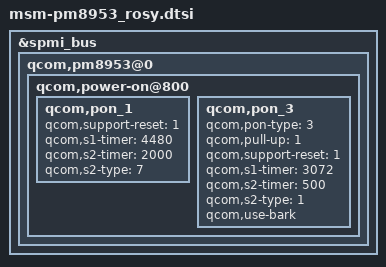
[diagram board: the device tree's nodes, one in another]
&spmi_bus {
	qcom,pm8953@0 {
		qcom,power-on@800 {
			qcom,pon_1 {
				qcom,support-reset = <1>;
				qcom,s1-timer = <4480>;
				qcom,s2-timer = <2000>;
				qcom,s2-type = <7>;
			};

			qcom,pon_3 {
				qcom,pon-type = <3>;
				qcom,pull-up = <1>;
				qcom,support-reset = <1>;
				qcom,s1-timer = <3072>;
				qcom,s2-timer = <500>;
				qcom,s2-type = <1>;
				qcom,use-bark;
			};
		};
	};
};
